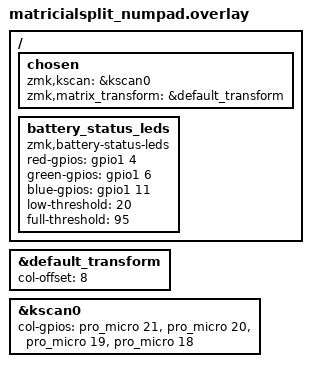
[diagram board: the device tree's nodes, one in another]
#include "matricialsplit.dtsi"

&default_transform {
    // Numpad uses columns 8-11
    col-offset = <8>;
};

&kscan0 {
    // Numpad columns
    col-gpios
        = <&pro_micro 21 (GPIO_ACTIVE_HIGH | GPIO_PULL_DOWN)>
        , <&pro_micro 20 (GPIO_ACTIVE_HIGH | GPIO_PULL_DOWN)>
        , <&pro_micro 19 (GPIO_ACTIVE_HIGH | GPIO_PULL_DOWN)>
        , <&pro_micro 18 (GPIO_ACTIVE_HIGH | GPIO_PULL_DOWN)>
        ;
};

/ {
    // Solo kscan principal para el numpad, sin encoders
    chosen {
        zmk,kscan = &kscan0;
        zmk,matrix_transform = &default_transform;
    };
};

/ {
    /*
     * Nodo principal del indicador de batería
     * - Node name: battery_status_leds (para referencia interna)
     * - Label: battery_status_leds (para poder referenciar con &battery_status_leds)
     * - Compatible: le dice a ZMK que driver usar
     */
    battery_status_leds: battery_status_leds {
        compatible = "zmk,battery-status-leds";
        status = "okay";  // Explícitamente habilitado (opt-in)
        
        /*
         * Configuración de pines GPIO
         * Formato: <&controlador pin flags>
         * - &gpio1: Puerto GPIO 1 del nRF52840
         * - Números: P1.04, P1.06, P1.11 según tu selección
         * - GPIO_ACTIVE_HIGH: LED se enciende con señal alta
         */
        red-gpios = <&gpio1 4 GPIO_ACTIVE_HIGH>;     // P1.04 - LED rojo
        green-gpios = <&gpio1 6 GPIO_ACTIVE_HIGH>;   // P1.06 - LED verde  
        blue-gpios = <&gpio1 11 GPIO_ACTIVE_HIGH>;   // P1.11 - LED azul
        
        /*
         * Configuración de umbrales (opcional)
         * Si se omiten, se usan los defaults (20 y 95)
         * Estos valores serán validados en compilación
         */
        low-threshold = <20>;   // Batería baja: menor a 20%
        full-threshold = <95>;  // Batería cargada: mayor o igual a 95%
    };
};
